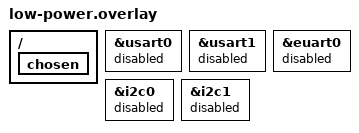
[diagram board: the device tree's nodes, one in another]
/*
 * Low-Power Devicetree Overlay
 * Disables USART1 and clears chosen console/shell-uart properties to disable serial hardware.
 */

/ {
	chosen {
		/delete-property/ zephyr,console;
		/delete-property/ zephyr,shell-uart;
	};
};

&usart0 {
	status = "disabled";
};

&usart1 {
	status = "disabled";
};

&euart0 {
	status = "disabled";
};

&i2c0 {
	status = "disabled";
};

&i2c1 {
	status = "disabled";
};
